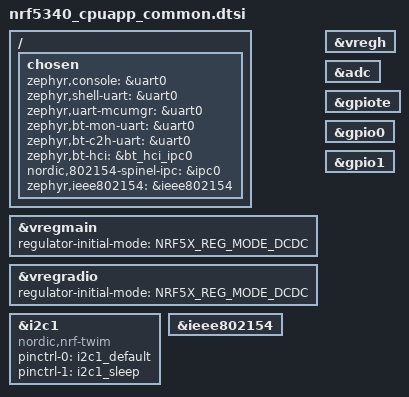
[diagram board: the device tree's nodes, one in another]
/*
 * Copyright (c) 2025 Daniel Kampert
 *
 * SPDX-License-Identifier: Apache-2.0
 */

#include <zephyr/dt-bindings/input/input-event-codes.h>

#include "nrf5340_cpuapp_common-pinctrl.dtsi"

/ {
    chosen {
        zephyr,console = &uart0;
        zephyr,shell-uart = &uart0;
        zephyr,uart-mcumgr = &uart0;
        zephyr,bt-mon-uart = &uart0;
        zephyr,bt-c2h-uart = &uart0;
        zephyr,bt-hci = &bt_hci_ipc0;
        nordic,802154-spinel-ipc = &ipc0;
        zephyr,ieee802154 = &ieee802154;
    };
};

&vregmain {
    regulator-initial-mode = <NRF5X_REG_MODE_DCDC>;
};

&vregradio {
    regulator-initial-mode = <NRF5X_REG_MODE_DCDC>;
};

&vregh {
    status = "okay";
};

&adc {
    status = "okay";
    #address-cells = <1>;
    #size-cells = <0>;
};

&gpiote {
    status = "okay";
};

&gpio0 {
    status = "okay";
};

&gpio1 {
    status = "okay";
};

&i2c1 {
    compatible = "nordic,nrf-twim";
    status = "okay";
    pinctrl-0 = <&i2c1_default>;
    pinctrl-1 = <&i2c1_sleep>;
    pinctrl-names = "default", "sleep";
};

&ieee802154 {
    status = "okay";
};

/* Include default memory partition configuration file */
#include <common/nordic/nrf5340_cpuapp_partition.dtsi>
